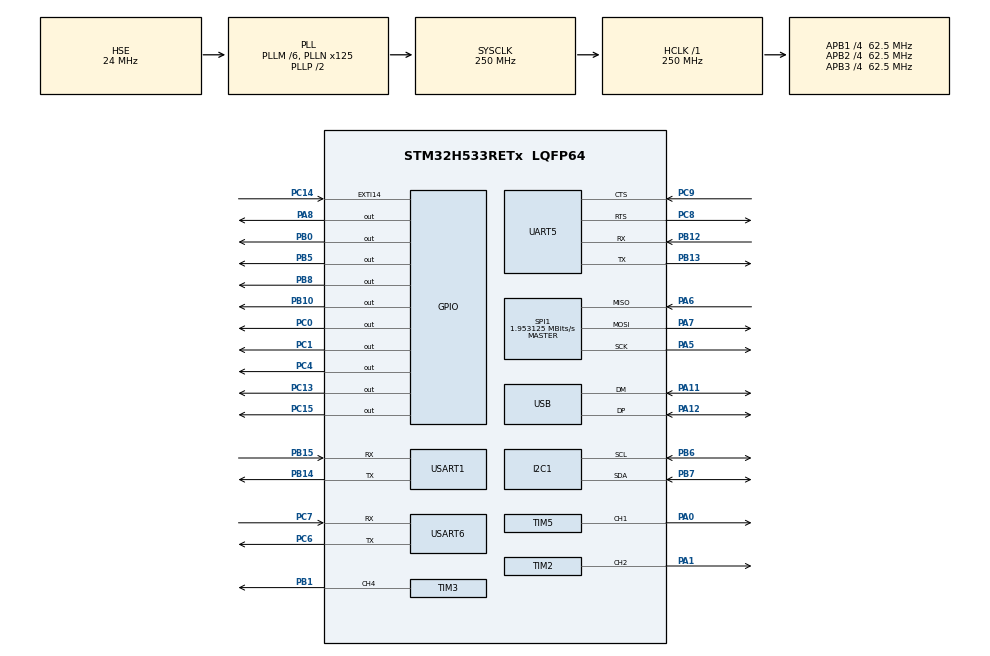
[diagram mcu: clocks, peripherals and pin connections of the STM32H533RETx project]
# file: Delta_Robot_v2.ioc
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BOOTPATH.BootPathName=LEGACY
BOOTPATH.UserSelectedBootPath=LEGACY
CORTEX_M33_NS.userName=CORTEX_M33
I2C1.Timing=0x2050517A
Mcu.Family=STM32H5
Mcu.Name=STM32H533RETx
Mcu.Package=LQFP64
NVIC.PriorityGroup=NVIC_PRIORITYGROUP_4
NVIC.TIM15_IRQn=true\:0\:0\:false\:false\:true\:true\:true\:true
NVIC.TIM2_IRQn=true\:0\:0\:false\:false\:true\:true\:true\:true
NVIC.TIM3_IRQn=true\:0\:0\:false\:false\:true\:true\:true\:true
NVIC.TIM5_IRQn=true\:0\:0\:false\:false\:true\:true\:true\:true
PA0.Signal=S_TIM5_CH1
PA1.Signal=S_TIM2_CH2
PA11.Mode=Device
PA11.Signal=USB_DM
PA12.Mode=Device
PA12.Signal=USB_DP
PA5.GPIO_PuPd=GPIO_NOPULL
PA5.Mode=Full_Duplex_Master
PA5.Signal=SPI1_SCK
PA6.GPIO_PuPd=GPIO_PULLUP
PA6.Mode=Full_Duplex_Master
PA6.Signal=SPI1_MISO
PA7.GPIO_PuPd=GPIO_NOPULL
PA7.Mode=Full_Duplex_Master
PA7.Signal=SPI1_MOSI
PA8.PinState=GPIO_PIN_SET
PA8.Signal=GPIO_Output
PB0.Signal=GPIO_Output
PB1.Signal=S_TIM3_CH4
PB10.PinState=GPIO_PIN_SET
PB10.Signal=GPIO_Output
PB12.Mode=Asynchronous
PB12.Signal=UART5_RX
PB13.Mode=Asynchronous
PB13.Signal=UART5_TX
PB14.Mode=Asynchronous
PB14.Signal=USART1_TX
PB15.Mode=Asynchronous
PB15.Signal=USART1_RX
PB5.PinState=GPIO_PIN_SET
PB5.Signal=GPIO_Output
PB6.Mode=I2C
PB6.Signal=I2C1_SCL
PB7.Mode=I2C
PB7.Signal=I2C1_SDA
PB8.Signal=GPIO_Output
PC0.Signal=GPIO_Output
PC1.Signal=GPIO_Output
PC13.Signal=GPIO_Output
PC14-OSC32_IN(OSC32_IN).Signal=GPXTI14
PC15-OSC32_OUT(OSC32_OUT).Signal=GPIO_Output
PC2.Signal=S_TIM4_CH4
PC4.Signal=GPIO_Output
PC6.Mode=Asynchronous
PC6.Signal=USART6_TX
PC7.Mode=Asynchronous
PC7.Signal=USART6_RX
PC8.Mode=CTS_RTS
PC8.Signal=UART5_RTS
PC9.Mode=CTS_RTS
PC9.Signal=UART5_CTS
PH0-OSC_IN(PH0).Mode=HSE-External-Oscillator
PH0-OSC_IN(PH0).Signal=RCC_OSC_IN
PH1-OSC_OUT(PH1).Mode=HSE-External-Oscillator
PH1-OSC_OUT(PH1).Signal=RCC_OSC_OUT
ProjectManager.HeapSize=0x200
ProjectManager.StackSize=0x400
ProjectManager.TargetToolchain=STM32CubeIDE
RCC.ADCFreq_Value=250000000
RCC.AHBFreq_Value=250000000
RCC.APB1CLKDivider=RCC_HCLK_DIV4
RCC.APB1Freq_Value=62500000
RCC.APB1TimFreq_Value=125000000
RCC.APB2CLKDivider=RCC_HCLK_DIV4
RCC.APB2Freq_Value=62500000
RCC.APB2TimFreq_Value=125000000
RCC.APB3CLKDivider=RCC_HCLK_DIV4
RCC.APB3Freq_Value=62500000
RCC.CSI_VALUE=4000000
RCC.CortexFreq_Value=250000000
RCC.EPOD_VALUE=24000000
RCC.HCLKFreq_Value=250000000
RCC.HSE_VALUE=24000000
RCC.HSI48_VALUE=48000000
RCC.HSI_VALUE=64000000
RCC.LSE_VALUE=32768
RCC.LSIRC_VALUE=32000
RCC.PLL1Q=8
RCC.PLLFRACN=0
RCC.PLLM=6
RCC.PLLN=125
RCC.PLLSourceVirtual=RCC_PLL1_SOURCE_HSE
RCC.SYSCLKFreq_VALUE=250000000
RCC.SYSCLKSource=RCC_SYSCLKSOURCE_PLLCLK
RCC.USBFreq_Value=48000000
RCC.VCOOutputFreq_Value=500000000
SH.S_TIM2_CH2.0=TIM2_CH2,Output Compare2 CH2
SH.S_TIM3_CH4.0=TIM3_CH4,Output Compare4 CH4
SH.S_TIM4_CH4.0=TIM4_CH4
SH.S_TIM5_CH1.0=TIM5_CH1,Output Compare1 CH1
SPI1.BaudRatePrescaler=SPI_BAUDRATEPRESCALER_32
SPI1.CLKPhase=SPI_PHASE_2EDGE
SPI1.CLKPolarity=SPI_POLARITY_LOW
SPI1.CalculateBaudRate=1.953125 MBits/s
SPI1.DataSize=SPI_DATASIZE_16BIT
SPI1.Direction=SPI_DIRECTION_2LINES
SPI1.FirstBit=SPI_FIRSTBIT_MSB
SPI1.Mode=SPI_MODE_MASTER
SPI1.VirtualType=VM_MASTER
TIM15.PeriodNoDither=124
TIM15.Prescaler=10
TIM2.AutoReloadPreload=TIM_AUTORELOAD_PRELOAD_DISABLE
TIM2.Channel-Output\ Compare2\ CH2=TIM_CHANNEL_2
TIM2.OCMode_2=TIM_OCMODE_TOGGLE
TIM2.PeriodNoDither=0x1
TIM2.Prescaler=249
TIM3.AutoReloadPreload=TIM_AUTORELOAD_PRELOAD_DISABLE
TIM3.Channel-Output\ Compare4\ CH4=TIM_CHANNEL_4
TIM3.OC4Preload=DISABLE
TIM3.OCMode_4=TIM_OCMODE_TOGGLE
TIM3.PeriodNoDither=0x1
TIM3.Prescaler=249
TIM3.PulseNoDither_4=0
TIM5.AutoReloadPreload=TIM_AUTORELOAD_PRELOAD_DISABLE
TIM5.Channel-Output\ Compare1\ CH1=TIM_CHANNEL_1
TIM5.OCMode_1=TIM_OCMODE_TOGGLE
TIM5.PeriodNoDither=0x1
TIM5.Prescaler=249
USART1.Parity=PARITY_NONE
USART1.VirtualMode-Asynchronous=VM_ASYNC
USART6.VirtualMode=VM_ASYNC
USB.VirtualMode=Device_Only
VP_BOOTPATH_VS_BOOTPATH.Mode=BP_Activate
VP_CORTEX_M33_NS_VS_Hclk.Mode=Hclk_Mode
VP_ICACHE_VS_ICACHE.Mode=DefaultMode
VP_MEMORYMAP_VS_MEMORYMAP.Mode=CurAppReg
VP_PWR_VS_DBSignals.Mode=DisableDeadBatterySignals
VP_PWR_VS_LPOM.Mode=PowerOptimisation
VP_PWR_VS_SECSignals.Mode=Security/Privilege
VP_TIM15_VS_ClockSourceINT.Mode=Internal
VP_TIM2_VS_ClockSourceINT.Mode=Internal
VP_TIM3_VS_ClockSourceINT.Mode=Internal
VP_TIM5_VS_ClockSourceINT.Mode=Internal
board=custom

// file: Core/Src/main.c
/* USER CODE BEGIN Header */
/**
  ******************************************************************************
  * @file           : main.c
  * @brief          : Main program body
  ******************************************************************************
  * @attention
  *
  * Copyright (c) 2024 STMicroelectronics.
  * All rights reserved.
  *
  * This software is licensed under terms that can be found in the LICENSE file
  * in the root directory of this software component.
  * If no LICENSE file comes with this software, it is provided AS-IS.
  *
  ******************************************************************************
  */
/* USER CODE END Header */
#include "main.h"

I2C_HandleTypeDef hi2c1;

SPI_HandleTypeDef hspi1;

TIM_HandleTypeDef htim2;
TIM_HandleTypeDef htim3;
TIM_HandleTypeDef htim5;
TIM_HandleTypeDef htim15;

UART_HandleTypeDef huart5;
UART_HandleTypeDef huart1;
UART_HandleTypeDef huart6;

PCD_HandleTypeDef hpcd_USB_DRD_FS;

/* USER CODE BEGIN PV */
uint8_t enter[] = {"\r\n"} ;
/* USER CODE END PV */

void SystemClock_Config(void);
static void MX_GPIO_Init(void);
static void MX_UART5_Init(void);
static void MX_USART1_UART_Init(void);
static void MX_USB_PCD_Init(void);
static void MX_I2C1_Init(void);
static void MX_SPI1_Init(void);
static void MX_USART6_UART_Init(void);
static void MX_TIM2_Init(void);
static void MX_TIM3_Init(void);
static void MX_TIM5_Init(void);
static void MX_TIM15_Init(void);
static void MX_ICACHE_Init(void);

int main(void)
{

  /* MCU Configuration--------------------------------------------------------*/

  /* Reset of all peripherals, Initializes the Flash interface and the Systick. */
  HAL_Init();

  /* Configure the system clock */
  SystemClock_Config();

  /* Initialize all configured peripherals */
  MX_GPIO_Init();
  MX_UART5_Init();
  MX_USART1_UART_Init();
  MX_USB_PCD_Init();
  MX_I2C1_Init();
  MX_SPI1_Init();
  MX_USART6_UART_Init();
  MX_TIM2_Init();
  MX_TIM3_Init();
  MX_TIM5_Init();
  MX_TIM15_Init();
  MX_ICACHE_Init();
  /* USER CODE BEGIN 2 */

  uint8_t tx_buff[60] = {"test \r\n"};
  //HAL_UART_Transmit(&huart1, tx_buff, 10, 1000);

  //sprintf(tx_buff, "%d \r\n", 0x3FFF&Hall_Sensor_Read_Magnitude(&hspi1, Hall_SS0_PORT, Hall_SS0_PIN));
  //HAL_UART_Transmit(&huart1, tx_buff, 10, 1000);

  //sprintf(tx_buff, "%d \r\n", 360*(0x3FFF&Hall_Sensor_Read_Angle(&hspi1, Hall_SS0_PORT, Hall_SS0_PIN))/0x3FFF); // @suppress("Float formatting support")
  //HAL_UART_Transmit(&huart1, tx_buff, 10, 1000);

  Relay_0_Set();
  HAL_Delay(200);
  Relay_1_Set();
  HAL_Delay(200);
  Relay_0_Reset();
  HAL_Delay(200);
  Relay_1_Reset();

  Zero_XYZ(&huart1, 0, 0, 0);
  //HAL_TIM_OC_Start_IT(&htim2,TIM_CHANNEL_2);
  //Frequency_Out(&htim2,10000);
  //HAL_TIM_OC_Start_IT(&htim3,TIM_CHANNEL_4);
  //HAL_TIM_OC_Start_IT(&htim5,TIM_CHANNEL_1);
  HAL_TIM_Base_Start_IT(&htim15);
  //Frequency_Out(&htim3,40000);
  //Frequency_Out(&htim5,40000);
  //Frequency_Out(&htim3,40000);
  //Frequency_Out(&htim2,40000);
  //HAL_GPIO_WritePin(GPIOC, GPIO_PIN_0, GPIO_PIN_SET);

  Menu_UART_Start(&huart1);
  /* USER CODE END 2 */

  /* Infinite loop */
  while (1)
  {

    /* USER CODE BEGIN 3 */
	  Menu_UART_Update(&huart1);
	 // sprintf(tx_buff, "\r\n %f \r\n",360*(double)((double)(0x3FFF&Hall_Sensor_Read_Angle(&hspi1, Hall_SS0_PORT, Hall_SS0_PIN))/0x3FFF)); // @suppress("Float formatting support")
	  //  HAL_UART_Transmit(&huart1, tx_buff, 10, 1000);

/*
 360*(double)((0x3FFF&Hall_Sensor_Read_Angle(&hspi1, Hall_SS0_PORT, Hall_SS0_PIN))/0x3FFF)
	  move (20000,20000,20000,M0_TIM, M0_CHANNEL, M1_TIM, M1_CHANNEL, M2_TIM, M2_CHANNEL);

	  HAL_Delay(1000);

	  move (0,0,0,M0_TIM, M0_CHANNEL, M1_TIM, M1_CHANNEL, M2_TIM, M2_CHANNEL);

	  HAL_Delay(1000);
*/
  }
  /* USER CODE END 3 */
}

void SystemClock_Config(void)
{
  RCC_OscInitTypeDef RCC_OscInitStruct = {0};
  RCC_ClkInitTypeDef RCC_ClkInitStruct = {0};

  /** Configure the main internal regulator output voltage
  */
  __HAL_PWR_VOLTAGESCALING_CONFIG(PWR_REGULATOR_VOLTAGE_SCALE0);

  while(!__HAL_PWR_GET_FLAG(PWR_FLAG_VOSRDY)) {}

  /** Initializes the RCC Oscillators according to the specified parameters
  * in the RCC_OscInitTypeDef structure.
  */
  RCC_OscInitStruct.OscillatorType = RCC_OSCILLATORTYPE_HSI48|RCC_OSCILLATORTYPE_HSE;
  RCC_OscInitStruct.HSEState = RCC_HSE_ON;
  RCC_OscInitStruct.HSI48State = RCC_HSI48_ON;
  RCC_OscInitStruct.PLL.PLLState = RCC_PLL_ON;
  RCC_OscInitStruct.PLL.PLLSource = RCC_PLL1_SOURCE_HSE;
  RCC_OscInitStruct.PLL.PLLM = 6;
  RCC_OscInitStruct.PLL.PLLN = 125;
  RCC_OscInitStruct.PLL.PLLP = 2;
  RCC_OscInitStruct.PLL.PLLQ = 8;
  RCC_OscInitStruct.PLL.PLLR = 2;
  RCC_OscInitStruct.PLL.PLLRGE = RCC_PLL1_VCIRANGE_2;
  RCC_OscInitStruct.PLL.PLLVCOSEL = RCC_PLL1_VCORANGE_WIDE;
  RCC_OscInitStruct.PLL.PLLFRACN = 0;
  if (HAL_RCC_OscConfig(&RCC_OscInitStruct) != HAL_OK)
  {
    Error_Handler();
  }

  /** Initializes the CPU, AHB and APB buses clocks
  */
  RCC_ClkInitStruct.ClockType = RCC_CLOCKTYPE_HCLK|RCC_CLOCKTYPE_SYSCLK
                              |RCC_CLOCKTYPE_PCLK1|RCC_CLOCKTYPE_PCLK2
                              |RCC_CLOCKTYPE_PCLK3;
  RCC_ClkInitStruct.SYSCLKSource = RCC_SYSCLKSOURCE_PLLCLK;
  RCC_ClkInitStruct.AHBCLKDivider = RCC_SYSCLK_DIV1;
  RCC_ClkInitStruct.APB1CLKDivider = RCC_HCLK_DIV4;
  RCC_ClkInitStruct.APB2CLKDivider = RCC_HCLK_DIV4;
  RCC_ClkInitStruct.APB3CLKDivider = RCC_HCLK_DIV4;

  if (HAL_RCC_ClockConfig(&RCC_ClkInitStruct, FLASH_LATENCY_5) != HAL_OK)
  {
    Error_Handler();
  }

  /** Configure the programming delay
  */
  __HAL_FLASH_SET_PROGRAM_DELAY(FLASH_PROGRAMMING_DELAY_2);
}

static void MX_I2C1_Init(void)
{

  hi2c1.Instance = I2C1;
  hi2c1.Init.Timing = 0x2050517A;
  hi2c1.Init.OwnAddress1 = 0;
  hi2c1.Init.AddressingMode = I2C_ADDRESSINGMODE_7BIT;
  hi2c1.Init.DualAddressMode = I2C_DUALADDRESS_DISABLE;
  hi2c1.Init.OwnAddress2 = 0;
  hi2c1.Init.OwnAddress2Masks = I2C_OA2_NOMASK;
  hi2c1.Init.GeneralCallMode = I2C_GENERALCALL_DISABLE;
  hi2c1.Init.NoStretchMode = I2C_NOSTRETCH_DISABLE;
  if (HAL_I2C_Init(&hi2c1) != HAL_OK)
  {
    Error_Handler();
  }

  /** Configure Analogue filter
  */
  if (HAL_I2CEx_ConfigAnalogFilter(&hi2c1, I2C_ANALOGFILTER_ENABLE) != HAL_OK)
  {
    Error_Handler();
  }

  /** Configure Digital filter
  */
  if (HAL_I2CEx_ConfigDigitalFilter(&hi2c1, 0) != HAL_OK)
  {
    Error_Handler();
  }

}

static void MX_ICACHE_Init(void)
{

  /** Enable instruction cache (default 2-ways set associative cache)
  */
  if (HAL_ICACHE_Enable() != HAL_OK)
  {
    Error_Handler();
  }

}

static void MX_SPI1_Init(void)
{

  /* SPI1 parameter configuration*/
  hspi1.Instance = SPI1;
  hspi1.Init.Mode = SPI_MODE_MASTER;
  hspi1.Init.Direction = SPI_DIRECTION_2LINES;
  hspi1.Init.DataSize = SPI_DATASIZE_16BIT;
  hspi1.Init.CLKPolarity = SPI_POLARITY_LOW;
  hspi1.Init.CLKPhase = SPI_PHASE_2EDGE;
  hspi1.Init.NSS = SPI_NSS_SOFT;
  hspi1.Init.BaudRatePrescaler = SPI_BAUDRATEPRESCALER_32;
  hspi1.Init.FirstBit = SPI_FIRSTBIT_MSB;
  hspi1.Init.TIMode = SPI_TIMODE_DISABLE;
  hspi1.Init.CRCCalculation = SPI_CRCCALCULATION_DISABLE;
  hspi1.Init.CRCPolynomial = 0x7;
  hspi1.Init.NSSPMode = SPI_NSS_PULSE_DISABLE;
  hspi1.Init.NSSPolarity = SPI_NSS_POLARITY_LOW;
  hspi1.Init.FifoThreshold = SPI_FIFO_THRESHOLD_01DATA;
  hspi1.Init.MasterSSIdleness = SPI_MASTER_SS_IDLENESS_00CYCLE;
  hspi1.Init.MasterInterDataIdleness = SPI_MASTER_INTERDATA_IDLENESS_00CYCLE;
  hspi1.Init.MasterReceiverAutoSusp = SPI_MASTER_RX_AUTOSUSP_DISABLE;
  hspi1.Init.MasterKeepIOState = SPI_MASTER_KEEP_IO_STATE_DISABLE;
  hspi1.Init.IOSwap = SPI_IO_SWAP_DISABLE;
  hspi1.Init.ReadyMasterManagement = SPI_RDY_MASTER_MANAGEMENT_INTERNALLY;
  hspi1.Init.ReadyPolarity = SPI_RDY_POLARITY_HIGH;
  if (HAL_SPI_Init(&hspi1) != HAL_OK)
  {
    Error_Handler();
  }

}

static void MX_TIM2_Init(void)
{

  TIM_ClockConfigTypeDef sClockSourceConfig = {0};
  TIM_MasterConfigTypeDef sMasterConfig = {0};
  TIM_OC_InitTypeDef sConfigOC = {0};

  htim2.Instance = TIM2;
  htim2.Init.Prescaler = 249;
  htim2.Init.CounterMode = TIM_COUNTERMODE_UP;
  htim2.Init.Period = 1;
  htim2.Init.ClockDivision = TIM_CLOCKDIVISION_DIV1;
  htim2.Init.AutoReloadPreload = TIM_AUTORELOAD_PRELOAD_DISABLE;
  if (HAL_TIM_Base_Init(&htim2) != HAL_OK)
  {
    Error_Handler();
  }
  sClockSourceConfig.ClockSource = TIM_CLOCKSOURCE_INTERNAL;
  if (HAL_TIM_ConfigClockSource(&htim2, &sClockSourceConfig) != HAL_OK)
  {
    Error_Handler();
  }
  if (HAL_TIM_OC_Init(&htim2) != HAL_OK)
  {
    Error_Handler();
  }
  sMasterConfig.MasterOutputTrigger = TIM_TRGO_RESET;
  sMasterConfig.MasterSlaveMode = TIM_MASTERSLAVEMODE_DISABLE;
  if (HAL_TIMEx_MasterConfigSynchronization(&htim2, &sMasterConfig) != HAL_OK)
  {
    Error_Handler();
  }
  sConfigOC.OCMode = TIM_OCMODE_TOGGLE;
  sConfigOC.Pulse = 0;
  sConfigOC.OCPolarity = TIM_OCPOLARITY_HIGH;
  sConfigOC.OCFastMode = TIM_OCFAST_DISABLE;
  if (HAL_TIM_OC_ConfigChannel(&htim2, &sConfigOC, TIM_CHANNEL_2) != HAL_OK)
  {
    Error_Handler();
  }
  HAL_TIM_MspPostInit(&htim2);

}

static void MX_TIM3_Init(void)
{

  TIM_ClockConfigTypeDef sClockSourceConfig = {0};
  TIM_MasterConfigTypeDef sMasterConfig = {0};
  TIM_OC_InitTypeDef sConfigOC = {0};

  htim3.Instance = TIM3;
  htim3.Init.Prescaler = 249;
  htim3.Init.CounterMode = TIM_COUNTERMODE_UP;
  htim3.Init.Period = 1;
  htim3.Init.ClockDivision = TIM_CLOCKDIVISION_DIV1;
  htim3.Init.AutoReloadPreload = TIM_AUTORELOAD_PRELOAD_DISABLE;
  if (HAL_TIM_Base_Init(&htim3) != HAL_OK)
  {
    Error_Handler();
  }
  sClockSourceConfig.ClockSource = TIM_CLOCKSOURCE_INTERNAL;
  if (HAL_TIM_ConfigClockSource(&htim3, &sClockSourceConfig) != HAL_OK)
  {
    Error_Handler();
  }
  if (HAL_TIM_OC_Init(&htim3) != HAL_OK)
  {
    Error_Handler();
  }
  sMasterConfig.MasterOutputTrigger = TIM_TRGO_RESET;
  sMasterConfig.MasterSlaveMode = TIM_MASTERSLAVEMODE_DISABLE;
  if (HAL_TIMEx_MasterConfigSynchronization(&htim3, &sMasterConfig) != HAL_OK)
  {
    Error_Handler();
  }
  sConfigOC.OCMode = TIM_OCMODE_TOGGLE;
  sConfigOC.Pulse = 0;
  sConfigOC.OCPolarity = TIM_OCPOLARITY_HIGH;
  sConfigOC.OCFastMode = TIM_OCFAST_DISABLE;
  if (HAL_TIM_OC_ConfigChannel(&htim3, &sConfigOC, TIM_CHANNEL_4) != HAL_OK)
  {
    Error_Handler();
  }
  HAL_TIM_MspPostInit(&htim3);

}

static void MX_TIM5_Init(void)
{

  TIM_ClockConfigTypeDef sClockSourceConfig = {0};
  TIM_MasterConfigTypeDef sMasterConfig = {0};
  TIM_OC_InitTypeDef sConfigOC = {0};

  htim5.Instance = TIM5;
  htim5.Init.Prescaler = 249;
  htim5.Init.CounterMode = TIM_COUNTERMODE_UP;
  htim5.Init.Period = 1;
  htim5.Init.ClockDivision = TIM_CLOCKDIVISION_DIV1;
  htim5.Init.AutoReloadPreload = TIM_AUTORELOAD_PRELOAD_DISABLE;
  if (HAL_TIM_Base_Init(&htim5) != HAL_OK)
  {
    Error_Handler();
  }
  sClockSourceConfig.ClockSource = TIM_CLOCKSOURCE_INTERNAL;
  if (HAL_TIM_ConfigClockSource(&htim5, &sClockSourceConfig) != HAL_OK)
  {
    Error_Handler();
  }
  if (HAL_TIM_OC_Init(&htim5) != HAL_OK)
  {
    Error_Handler();
  }
  sMasterConfig.MasterOutputTrigger = TIM_TRGO_RESET;
  sMasterConfig.MasterSlaveMode = TIM_MASTERSLAVEMODE_DISABLE;
  if (HAL_TIMEx_MasterConfigSynchronization(&htim5, &sMasterConfig) != HAL_OK)
  {
    Error_Handler();
  }
  sConfigOC.OCMode = TIM_OCMODE_TOGGLE;
  sConfigOC.Pulse = 0;
  sConfigOC.OCPolarity = TIM_OCPOLARITY_HIGH;
  sConfigOC.OCFastMode = TIM_OCFAST_DISABLE;
  if (HAL_TIM_OC_ConfigChannel(&htim5, &sConfigOC, TIM_CHANNEL_1) != HAL_OK)
  {
    Error_Handler();
  }
  HAL_TIM_MspPostInit(&htim5);

}

static void MX_TIM15_Init(void)
{

  TIM_ClockConfigTypeDef sClockSourceConfig = {0};
  TIM_MasterConfigTypeDef sMasterConfig = {0};

  htim15.Instance = TIM15;
  htim15.Init.Prescaler = 10;
  htim15.Init.CounterMode = TIM_COUNTERMODE_UP;
  htim15.Init.Period = 124;
  htim15.Init.ClockDivision = TIM_CLOCKDIVISION_DIV1;
  htim15.Init.RepetitionCounter = 0;
  htim15.Init.AutoReloadPreload = TIM_AUTORELOAD_PRELOAD_DISABLE;
  if (HAL_TIM_Base_Init(&htim15) != HAL_OK)
  {
    Error_Handler();
  }
  sClockSourceConfig.ClockSource = TIM_CLOCKSOURCE_INTERNAL;
  if (HAL_TIM_ConfigClockSource(&htim15, &sClockSourceConfig) != HAL_OK)
  {
    Error_Handler();
  }
  sMasterConfig.MasterOutputTrigger = TIM_TRGO_RESET;
  sMasterConfig.MasterSlaveMode = TIM_MASTERSLAVEMODE_DISABLE;
  if (HAL_TIMEx_MasterConfigSynchronization(&htim15, &sMasterConfig) != HAL_OK)
  {
    Error_Handler();
  }

}

static void MX_UART5_Init(void)
{

  huart5.Instance = UART5;
  huart5.Init.BaudRate = 115200;
  huart5.Init.WordLength = UART_WORDLENGTH_8B;
  huart5.Init.StopBits = UART_STOPBITS_1;
  huart5.Init.Parity = UART_PARITY_NONE;
  huart5.Init.Mode = UART_MODE_TX_RX;
  huart5.Init.HwFlowCtl = UART_HWCONTROL_RTS_CTS;
  huart5.Init.OverSampling = UART_OVERSAMPLING_16;
  huart5.Init.OneBitSampling = UART_ONE_BIT_SAMPLE_DISABLE;
  huart5.Init.ClockPrescaler = UART_PRESCALER_DIV1;
  huart5.AdvancedInit.AdvFeatureInit = UART_ADVFEATURE_NO_INIT;
  if (HAL_UART_Init(&huart5) != HAL_OK)
  {
    Error_Handler();
  }
  if (HAL_UARTEx_SetTxFifoThreshold(&huart5, UART_TXFIFO_THRESHOLD_1_8) != HAL_OK)
  {
    Error_Handler();
  }
  if (HAL_UARTEx_SetRxFifoThreshold(&huart5, UART_RXFIFO_THRESHOLD_1_8) != HAL_OK)
  {
    Error_Handler();
  }
  if (HAL_UARTEx_DisableFifoMode(&huart5) != HAL_OK)
  {
    Error_Handler();
  }

}

static void MX_USART1_UART_Init(void)
{

  huart1.Instance = USART1;
  huart1.Init.BaudRate = 115200;
  huart1.Init.WordLength = UART_WORDLENGTH_8B;
  huart1.Init.StopBits = UART_STOPBITS_1;
  huart1.Init.Parity = UART_PARITY_NONE;
  huart1.Init.Mode = UART_MODE_TX_RX;
  huart1.Init.HwFlowCtl = UART_HWCONTROL_NONE;
  huart1.Init.OverSampling = UART_OVERSAMPLING_16;
  huart1.Init.OneBitSampling = UART_ONE_BIT_SAMPLE_DISABLE;
  huart1.Init.ClockPrescaler = UART_PRESCALER_DIV1;
  huart1.AdvancedInit.AdvFeatureInit = UART_ADVFEATURE_NO_INIT;
  if (HAL_UART_Init(&huart1) != HAL_OK)
  {
    Error_Handler();
  }
  if (HAL_UARTEx_SetTxFifoThreshold(&huart1, UART_TXFIFO_THRESHOLD_1_8) != HAL_OK)
  {
    Error_Handler();
  }
  if (HAL_UARTEx_SetRxFifoThreshold(&huart1, UART_RXFIFO_THRESHOLD_1_8) != HAL_OK)
  {
    Error_Handler();
  }
  if (HAL_UARTEx_DisableFifoMode(&huart1) != HAL_OK)
  {
    Error_Handler();
  }

}

static void MX_USART6_UART_Init(void)
{

  huart6.Instance = USART6;
  huart6.Init.BaudRate = 115200;
  huart6.Init.WordLength = UART_WORDLENGTH_8B;
  huart6.Init.StopBits = UART_STOPBITS_1;
  huart6.Init.Parity = UART_PARITY_NONE;
  huart6.Init.Mode = UART_MODE_TX_RX;
  huart6.Init.HwFlowCtl = UART_HWCONTROL_NONE;
  huart6.Init.OverSampling = UART_OVERSAMPLING_16;
  huart6.Init.OneBitSampling = UART_ONE_BIT_SAMPLE_DISABLE;
  huart6.Init.ClockPrescaler = UART_PRESCALER_DIV1;
  huart6.AdvancedInit.AdvFeatureInit = UART_ADVFEATURE_NO_INIT;
  if (HAL_UART_Init(&huart6) != HAL_OK)
  {
    Error_Handler();
  }
  if (HAL_UARTEx_SetTxFifoThreshold(&huart6, UART_TXFIFO_THRESHOLD_1_8) != HAL_OK)
  {
    Error_Handler();
  }
  if (HAL_UARTEx_SetRxFifoThreshold(&huart6, UART_RXFIFO_THRESHOLD_1_8) != HAL_OK)
  {
    Error_Handler();
  }
  if (HAL_UARTEx_DisableFifoMode(&huart6) != HAL_OK)
  {
    Error_Handler();
  }

}

static void MX_USB_PCD_Init(void)
{

  hpcd_USB_DRD_FS.Instance = USB_DRD_FS;
  hpcd_USB_DRD_FS.Init.dev_endpoints = 8;
  hpcd_USB_DRD_FS.Init.speed = USBD_FS_SPEED;
  hpcd_USB_DRD_FS.Init.phy_itface = PCD_PHY_EMBEDDED;
  hpcd_USB_DRD_FS.Init.Sof_enable = DISABLE;
  hpcd_USB_DRD_FS.Init.low_power_enable = DISABLE;
  hpcd_USB_DRD_FS.Init.lpm_enable = DISABLE;
  hpcd_USB_DRD_FS.Init.battery_charging_enable = DISABLE;
  hpcd_USB_DRD_FS.Init.vbus_sensing_enable = DISABLE;
  hpcd_USB_DRD_FS.Init.bulk_doublebuffer_enable = DISABLE;
  hpcd_USB_DRD_FS.Init.iso_singlebuffer_enable = DISABLE;
  if (HAL_PCD_Init(&hpcd_USB_DRD_FS) != HAL_OK)
  {
    Error_Handler();
  }

}

static void MX_GPIO_Init(void)
{
  GPIO_InitTypeDef GPIO_InitStruct = {0};

  /* GPIO Ports Clock Enable */
  __HAL_RCC_GPIOC_CLK_ENABLE();
  __HAL_RCC_GPIOH_CLK_ENABLE();
  __HAL_RCC_GPIOA_CLK_ENABLE();
  __HAL_RCC_GPIOB_CLK_ENABLE();

  /*Configure GPIO pin Output Level */
  HAL_GPIO_WritePin(GPIOC, GPIO_PIN_13|GPIO_PIN_15|GPIO_PIN_0|GPIO_PIN_1
                          |GPIO_PIN_4, GPIO_PIN_RESET);

  /*Configure GPIO pin Output Level */
  HAL_GPIO_WritePin(GPIOB, GPIO_PIN_0|GPIO_PIN_8, GPIO_PIN_RESET);

  /*Configure GPIO pin Output Level */
  HAL_GPIO_WritePin(GPIOB, GPIO_PIN_10|GPIO_PIN_5, GPIO_PIN_SET);

  /*Configure GPIO pin Output Level */
  HAL_GPIO_WritePin(GPIOA, GPIO_PIN_8, GPIO_PIN_SET);

  /*Configure GPIO pins : PC13 PC15 PC0 PC1
                           PC4 */
  GPIO_InitStruct.Pin = GPIO_PIN_13|GPIO_PIN_15|GPIO_PIN_0|GPIO_PIN_1
                          |GPIO_PIN_4;
  GPIO_InitStruct.Mode = GPIO_MODE_OUTPUT_PP;
  GPIO_InitStruct.Pull = GPIO_NOPULL;
  GPIO_InitStruct.Speed = GPIO_SPEED_FREQ_LOW;
  HAL_GPIO_Init(GPIOC, &GPIO_InitStruct);

  /*Configure GPIO pin : PC14 */
  GPIO_InitStruct.Pin = GPIO_PIN_14;
  GPIO_InitStruct.Mode = GPIO_MODE_IT_RISING;
  GPIO_InitStruct.Pull = GPIO_NOPULL;
  HAL_GPIO_Init(GPIOC, &GPIO_InitStruct);

  /*Configure GPIO pin : PC2 */
  GPIO_InitStruct.Pin = GPIO_PIN_2;
  GPIO_InitStruct.Mode = GPIO_MODE_AF_PP;
  GPIO_InitStruct.Pull = GPIO_NOPULL;
  GPIO_InitStruct.Speed = GPIO_SPEED_FREQ_LOW;
  GPIO_InitStruct.Alternate = GPIO_AF2_TIM4;
  HAL_GPIO_Init(GPIOC, &GPIO_InitStruct);

  /*Configure GPIO pins : PB0 PB10 PB5 PB8 */
  GPIO_InitStruct.Pin = GPIO_PIN_0|GPIO_PIN_10|GPIO_PIN_5|GPIO_PIN_8;
  GPIO_InitStruct.Mode = GPIO_MODE_OUTPUT_PP;
  GPIO_InitStruct.Pull = GPIO_NOPULL;
  GPIO_InitStruct.Speed = GPIO_SPEED_FREQ_LOW;
  HAL_GPIO_Init(GPIOB, &GPIO_InitStruct);

  /*Configure GPIO pin : PA8 */
  GPIO_InitStruct.Pin = GPIO_PIN_8;
  GPIO_InitStruct.Mode = GPIO_MODE_OUTPUT_PP;
  GPIO_InitStruct.Pull = GPIO_NOPULL;
  GPIO_InitStruct.Speed = GPIO_SPEED_FREQ_LOW;
  HAL_GPIO_Init(GPIOA, &GPIO_InitStruct);

}

void Error_Handler(void)
{
  __disable_irq();
  while (1)
  {
  }
}
